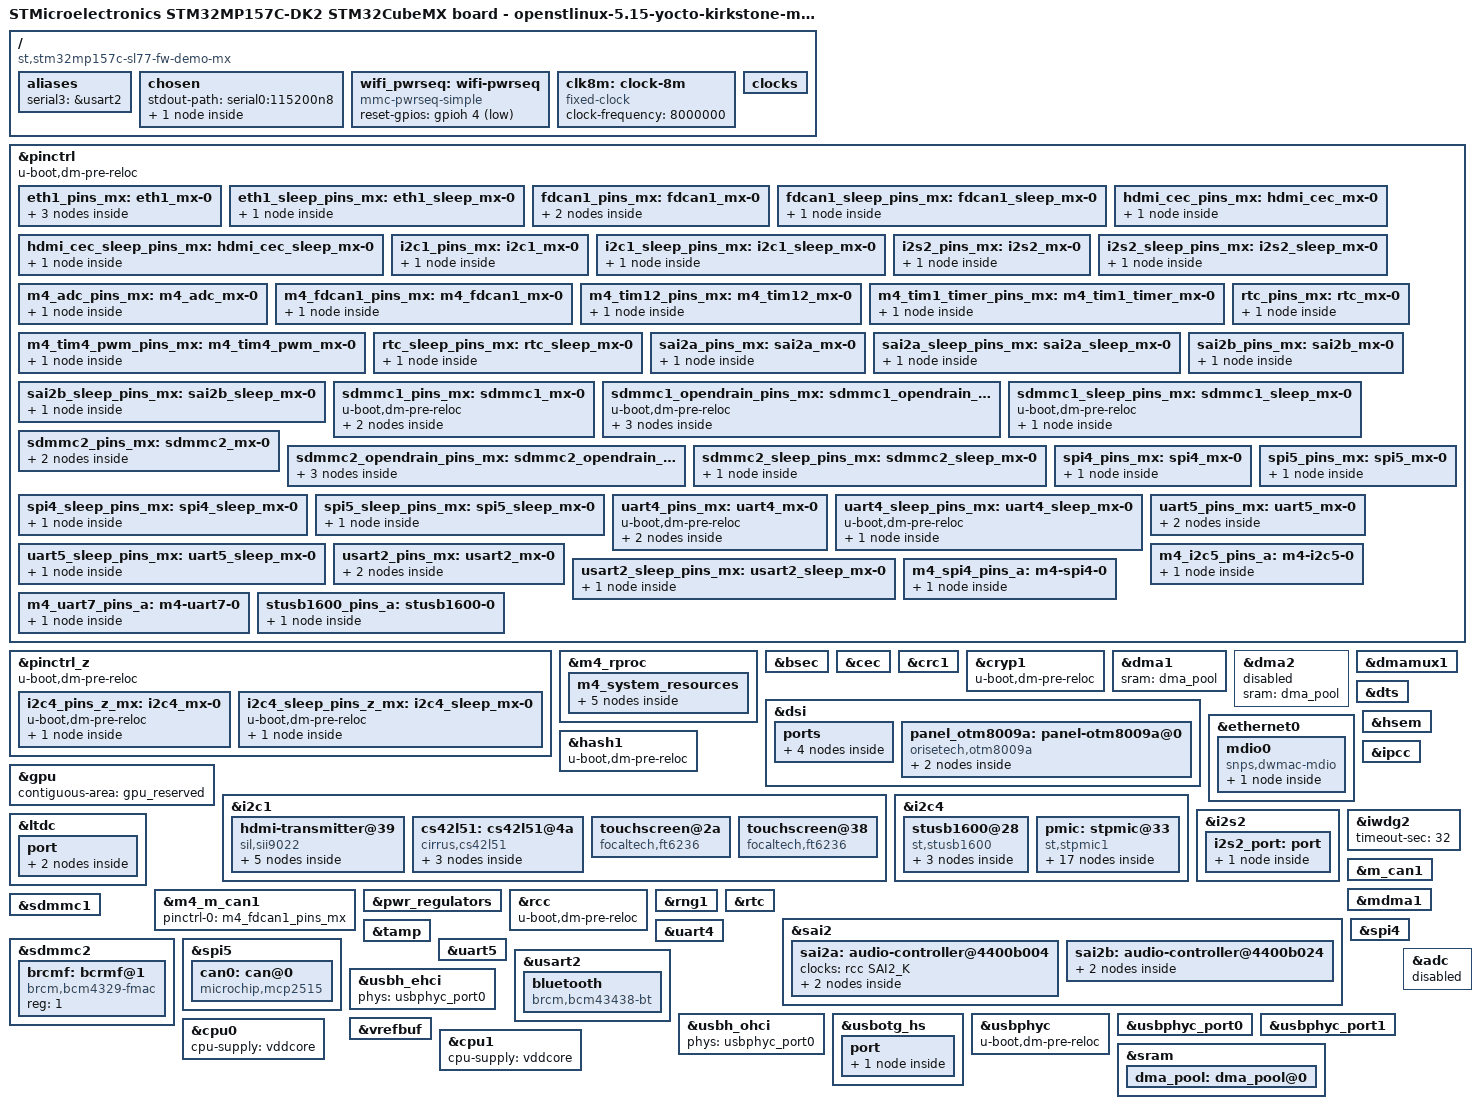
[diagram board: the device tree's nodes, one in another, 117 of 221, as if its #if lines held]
/*
 * Copyright (C) 2021 Slave77 - All Rights Reserved
 * Author: Slave77 <henry.slave77@gmail.com>
 */

/* 
 * For more information on Device Tree configuration, please refer to
 * https://wiki.st.com/stm32mpu/wiki/Category:Device_tree_configuration
 */

/dts-v1/;
#include <dt-bindings/pinctrl/stm32-pinfunc.h>

#include "stm32mp157.dtsi"
#include "stm32mp15xc.dtsi"
#include "stm32mp15-pinctrl.dtsi"
#include "stm32mp15xxac-pinctrl.dtsi"
#include "stm32mp15xx-dkx.dtsi"

/* USER CODE BEGIN includes */
#include <dt-bindings/mfd/st,stpmic1.h>
#include <dt-bindings/rtc/rtc-stm32.h>

/* USER CODE END includes */

/* USER CODE BEGIN defines */
#define USE_MCP2515

/* USER CODE END defines */


/ {
	model = "STMicroelectronics STM32MP157C-DK2 STM32CubeMX board - openstlinux-5.15-yocto-kirkstone-mp1-v22.06.15";
	compatible = "st,stm32mp157c-sl77-fw-demo-mx", "st,stm32mp157";

	aliases {
		serial3 = &usart2;
	};

	chosen {
		#address-cells = <1>;
		#size-cells = <1>;
		ranges;
		stdout-path = "serial0:115200n8";

		framebuffer {
			compatible = "simple-framebuffer";
			clocks = <&rcc LTDC_PX>;
			status = "disabled";
		};
	};

	wifi_pwrseq: wifi-pwrseq {
		compatible = "mmc-pwrseq-simple";
		reset-gpios = <&gpioh 4 GPIO_ACTIVE_LOW>;
	};

	/* Fixed crystal dedicated to mcp251x */
	clk8m: clock-8m {
		compatible = "fixed-clock";
		#clock-cells = <0>;
		clock-frequency = <8000000>;
	};
	/* USER CODE END root */

	clocks {
		/* USER CODE BEGIN clocks */
		/* USER CODE END clocks */

	};

}; /*root*/

&pinctrl {
	u-boot,dm-pre-reloc;

	eth1_pins_mx: eth1_mx-0 {
		pins1 {
			pinmux = <STM32_PINMUX('A', 1, AF11)>, /* ETH1_RX_CLK */
					 <STM32_PINMUX('A', 7, AF11)>, /* ETH1_RX_CTL */
					 <STM32_PINMUX('B', 0, AF11)>, /* ETH1_RXD2 */
					 <STM32_PINMUX('B', 1, AF11)>, /* ETH1_RXD3 */
					 <STM32_PINMUX('C', 4, AF11)>, /* ETH1_RXD0 */
					 <STM32_PINMUX('C', 5, AF11)>; /* ETH1_RXD1 */
			bias-disable;
		};
		pins2 {
			pinmux = <STM32_PINMUX('A', 2, AF11)>; /* ETH1_MDIO */
			bias-disable;
			drive-push-pull;
			slew-rate = <0>;
		};
		pins3 {
			pinmux = <STM32_PINMUX('B', 11, AF11)>, /* ETH1_TX_CTL */
					 <STM32_PINMUX('C', 1, AF11)>, /* ETH1_MDC */
					 <STM32_PINMUX('C', 2, AF11)>, /* ETH1_TXD2 */
					 <STM32_PINMUX('E', 2, AF11)>, /* ETH1_TXD3 */
					 <STM32_PINMUX('G', 4, AF11)>, /* ETH1_GTX_CLK */
					 <STM32_PINMUX('G', 5, AF11)>, /* ETH1_CLK125 */
					 <STM32_PINMUX('G', 13, AF11)>, /* ETH1_TXD0 */
					 <STM32_PINMUX('G', 14, AF11)>; /* ETH1_TXD1 */
			bias-disable;
			drive-push-pull;
			slew-rate = <2>;
		};
	};

	eth1_sleep_pins_mx: eth1_sleep_mx-0 {
		pins {
			pinmux = <STM32_PINMUX('A', 1, ANALOG)>, /* ETH1_RX_CLK */
					 <STM32_PINMUX('A', 2, ANALOG)>, /* ETH1_MDIO */
					 <STM32_PINMUX('A', 7, ANALOG)>, /* ETH1_RX_CTL */
					 <STM32_PINMUX('B', 0, ANALOG)>, /* ETH1_RXD2 */
					 <STM32_PINMUX('B', 1, ANALOG)>, /* ETH1_RXD3 */
					 <STM32_PINMUX('B', 11, ANALOG)>, /* ETH1_TX_CTL */
					 <STM32_PINMUX('C', 1, ANALOG)>, /* ETH1_MDC */
					 <STM32_PINMUX('C', 2, ANALOG)>, /* ETH1_TXD2 */
					 <STM32_PINMUX('C', 4, ANALOG)>, /* ETH1_RXD0 */
					 <STM32_PINMUX('C', 5, ANALOG)>, /* ETH1_RXD1 */
					 <STM32_PINMUX('E', 2, ANALOG)>, /* ETH1_TXD3 */
					 <STM32_PINMUX('G', 4, ANALOG)>, /* ETH1_GTX_CLK */
					 <STM32_PINMUX('G', 5, ANALOG)>, /* ETH1_CLK125 */
					 <STM32_PINMUX('G', 13, ANALOG)>, /* ETH1_TXD0 */
					 <STM32_PINMUX('G', 14, ANALOG)>; /* ETH1_TXD1 */
		};
	};

#ifdef CONFIG_FDCAN1_ON
	fdcan1_pins_mx: fdcan1_mx-0 {
		pins1 {
			pinmux = <STM32_PINMUX('A', 11, AF9)>; /* FDCAN1_RX */
			bias-disable;
		};
		pins2 {
			pinmux = <STM32_PINMUX('A', 12, AF9)>; /* FDCAN1_TX */
			bias-disable;
			drive-push-pull;
			slew-rate = <1>;
		};
	};

	fdcan1_sleep_pins_mx: fdcan1_sleep_mx-0 {
		pins {
			pinmux = <STM32_PINMUX('A', 11, ANALOG)>, /* FDCAN1_RX */
					 <STM32_PINMUX('A', 12, ANALOG)>; /* FDCAN1_TX */
		};
	};
#endif

	hdmi_cec_pins_mx: hdmi_cec_mx-0 {
		pins {
			pinmux = <STM32_PINMUX('B', 6, AF5)>; /* CEC */
			bias-disable;
			drive-open-drain;
			slew-rate = <0>;
		};
	};

	hdmi_cec_sleep_pins_mx: hdmi_cec_sleep_mx-0 {
		pins {
			pinmux = <STM32_PINMUX('B', 6, ANALOG)>; /* CEC */
		};
	};

	i2c1_pins_mx: i2c1_mx-0 {
		pins {
			pinmux = <STM32_PINMUX('D', 12, AF5)>, /* I2C1_SCL */
					 <STM32_PINMUX('F', 15, AF5)>; /* I2C1_SDA */
			bias-disable;
			drive-open-drain;
			slew-rate = <0>;
		};
	};

	i2c1_sleep_pins_mx: i2c1_sleep_mx-0 {
		pins {
			pinmux = <STM32_PINMUX('D', 12, ANALOG)>, /* I2C1_SCL */
					 <STM32_PINMUX('F', 15, ANALOG)>; /* I2C1_SDA */
		};
	};

	i2s2_pins_mx: i2s2_mx-0 {
		pins {
			pinmux = <STM32_PINMUX('A', 9, AF5)>, /* I2S2_CK */
					 <STM32_PINMUX('B', 9, AF5)>, /* I2S2_WS */
					 <STM32_PINMUX('I', 3, AF5)>; /* I2S2_SDO */
			bias-disable;
			drive-push-pull;
			slew-rate = <1>;
		};
	};

	i2s2_sleep_pins_mx: i2s2_sleep_mx-0 {
		pins {
			pinmux = <STM32_PINMUX('A', 9, ANALOG)>, /* I2S2_CK */
					 <STM32_PINMUX('B', 9, ANALOG)>, /* I2S2_WS */
					 <STM32_PINMUX('I', 3, ANALOG)>; /* I2S2_SDO */
		};
	};

	m4_adc_pins_mx: m4_adc_mx-0 {
		pins {
			pinmux = <STM32_PINMUX('A', 4, ANALOG)>, /* ADC1_INP18 */
					 <STM32_PINMUX('A', 5, ANALOG)>, /* ADC1_INP19 */
					 <STM32_PINMUX('F', 12, ANALOG)>; /* ADC1_INP6 */
		};
	};

	m4_fdcan1_pins_mx: m4_fdcan1_mx-0 {
		pins {
			pinmux = <STM32_PINMUX('A', 11, RSVD)>, /* FDCAN1_RX */
					 <STM32_PINMUX('A', 12, RSVD)>; /* FDCAN1_TX */
		};
	};

	m4_tim12_pins_mx: m4_tim12_mx-0 {
		pins {
			pinmux = <STM32_PINMUX('H', 6, RSVD)>; /* TIM12_CH1 */
		};
	};

	m4_tim1_timer_pins_mx: m4_tim1_timer_mx-0 {
		pins {
			pinmux = <STM32_PINMUX('A', 8, RSVD)>, /* TIM1_CH1 */
					 <STM32_PINMUX('E', 11, RSVD)>; /* TIM1_CH2 */
		};
	};

	m4_tim4_pwm_pins_mx: m4_tim4_pwm_mx-0 {
		pins {
			pinmux = <STM32_PINMUX('D', 14, RSVD)>, /* TIM4_CH3 */
					 <STM32_PINMUX('D', 15, RSVD)>; /* TIM4_CH4 */
		};
	};

	rtc_pins_mx: rtc_mx-0 {
		pins {
			pinmux = <STM32_PINMUX('I', 8, ANALOG)>; /* RTC_LSCO */
		};
	};

	rtc_sleep_pins_mx: rtc_sleep_mx-0 {
		pins {
			pinmux = <STM32_PINMUX('I', 8, ANALOG)>; /* RTC_LSCO */
		};
	};

	sai2a_pins_mx: sai2a_mx-0 {
		pins {
			pinmux = <STM32_PINMUX('E', 0, AF10)>, /* SAI2_MCLK_A */
					 <STM32_PINMUX('I', 5, AF10)>, /* SAI2_SCK_A */
					 <STM32_PINMUX('I', 6, AF10)>, /* SAI2_SD_A */
					 <STM32_PINMUX('I', 7, AF10)>; /* SAI2_FS_A */
			bias-disable;
			drive-push-pull;
			slew-rate = <0>;
		};
	};

	sai2a_sleep_pins_mx: sai2a_sleep_mx-0 {
		pins {
			pinmux = <STM32_PINMUX('E', 0, ANALOG)>, /* SAI2_MCLK_A */
					 <STM32_PINMUX('I', 5, ANALOG)>, /* SAI2_SCK_A */
					 <STM32_PINMUX('I', 6, ANALOG)>, /* SAI2_SD_A */
					 <STM32_PINMUX('I', 7, ANALOG)>; /* SAI2_FS_A */
		};
	};

	sai2b_pins_mx: sai2b_mx-0 {
		pins {
			pinmux = <STM32_PINMUX('F', 11, AF10)>; /* SAI2_SD_B */
			bias-disable;
			drive-push-pull;
			slew-rate = <0>;
		};
	};

	sai2b_sleep_pins_mx: sai2b_sleep_mx-0 {
		pins {
			pinmux = <STM32_PINMUX('F', 11, ANALOG)>; /* SAI2_SD_B */
		};
	};

	sdmmc1_pins_mx: sdmmc1_mx-0 {
		u-boot,dm-pre-reloc;
		pins1 {
			u-boot,dm-pre-reloc;
			pinmux = <STM32_PINMUX('C', 8, AF12)>, /* SDMMC1_D0 */
					 <STM32_PINMUX('C', 9, AF12)>, /* SDMMC1_D1 */
					 <STM32_PINMUX('C', 10, AF12)>, /* SDMMC1_D2 */
					 <STM32_PINMUX('C', 11, AF12)>, /* SDMMC1_D3 */
					 <STM32_PINMUX('D', 2, AF12)>; /* SDMMC1_CMD */
			bias-disable;
			drive-push-pull;
			slew-rate = <1>;
		};
		pins2 {
			u-boot,dm-pre-reloc;
			pinmux = <STM32_PINMUX('C', 12, AF12)>; /* SDMMC1_CK */
			bias-disable;
			drive-push-pull;
			slew-rate = <3>;
		};
	};

	sdmmc1_opendrain_pins_mx: sdmmc1_opendrain_mx-0 {
		u-boot,dm-pre-reloc;
		pins1 {
			u-boot,dm-pre-reloc;
			pinmux = <STM32_PINMUX('C', 8, AF12)>, /* SDMMC1_D0 */
					 <STM32_PINMUX('C', 9, AF12)>, /* SDMMC1_D1 */
					 <STM32_PINMUX('C', 10, AF12)>, /* SDMMC1_D2 */
					 <STM32_PINMUX('C', 11, AF12)>; /* SDMMC1_D3 */
			bias-disable;
			drive-push-pull;
			slew-rate = <1>;
		};
		pins2 {
			u-boot,dm-pre-reloc;
			pinmux = <STM32_PINMUX('C', 12, AF12)>; /* SDMMC1_CK */
			bias-disable;
			drive-push-pull;
			slew-rate = <3>;
		};
		pins3 {
			u-boot,dm-pre-reloc;
			pinmux = <STM32_PINMUX('D', 2, AF12)>; /* SDMMC1_CMD */
			bias-disable;
			drive-open-drain;
			slew-rate = <1>;
		};
	};

	sdmmc1_sleep_pins_mx: sdmmc1_sleep_mx-0 {
		u-boot,dm-pre-reloc;
		pins {
			u-boot,dm-pre-reloc;
			pinmux = <STM32_PINMUX('C', 8, ANALOG)>, /* SDMMC1_D0 */
					 <STM32_PINMUX('C', 9, ANALOG)>, /* SDMMC1_D1 */
					 <STM32_PINMUX('C', 10, ANALOG)>, /* SDMMC1_D2 */
					 <STM32_PINMUX('C', 11, ANALOG)>, /* SDMMC1_D3 */
					 <STM32_PINMUX('C', 12, ANALOG)>, /* SDMMC1_CK */
					 <STM32_PINMUX('D', 2, ANALOG)>; /* SDMMC1_CMD */
		};
	};

	sdmmc2_pins_mx: sdmmc2_mx-0 {
		pins1 {
			pinmux = <STM32_PINMUX('B', 3, AF9)>, /* SDMMC2_D2 */
					 <STM32_PINMUX('B', 4, AF9)>, /* SDMMC2_D3 */
					 <STM32_PINMUX('B', 14, AF9)>, /* SDMMC2_D0 */
					 <STM32_PINMUX('B', 15, AF9)>, /* SDMMC2_D1 */
					 <STM32_PINMUX('G', 6, AF10)>; /* SDMMC2_CMD */
			bias-disable;
			drive-push-pull;
			slew-rate = <1>;
		};
		pins2 {
			pinmux = <STM32_PINMUX('E', 3, AF9)>; /* SDMMC2_CK */
			bias-disable;
			drive-push-pull;
			slew-rate = <3>;
		};
	};

	sdmmc2_opendrain_pins_mx: sdmmc2_opendrain_mx-0 {
		pins1 {
			pinmux = <STM32_PINMUX('B', 3, AF9)>, /* SDMMC2_D2 */
					 <STM32_PINMUX('B', 4, AF9)>, /* SDMMC2_D3 */
					 <STM32_PINMUX('B', 14, AF9)>, /* SDMMC2_D0 */
					 <STM32_PINMUX('B', 15, AF9)>; /* SDMMC2_D1 */
			bias-disable;
			drive-push-pull;
			slew-rate = <1>;
		};
		pins2 {
			pinmux = <STM32_PINMUX('E', 3, AF9)>; /* SDMMC2_CK */
			bias-disable;
			drive-push-pull;
			slew-rate = <3>;
		};
		pins3 {
			pinmux = <STM32_PINMUX('G', 6, AF10)>; /* SDMMC2_CMD */
			bias-disable;
			drive-open-drain;
			slew-rate = <1>;
		};
	};

	sdmmc2_sleep_pins_mx: sdmmc2_sleep_mx-0 {
		pins {
			pinmux = <STM32_PINMUX('B', 3, ANALOG)>, /* SDMMC2_D2 */
					 <STM32_PINMUX('B', 4, ANALOG)>, /* SDMMC2_D3 */
					 <STM32_PINMUX('B', 14, ANALOG)>, /* SDMMC2_D0 */
					 <STM32_PINMUX('B', 15, ANALOG)>, /* SDMMC2_D1 */
					 <STM32_PINMUX('E', 3, ANALOG)>, /* SDMMC2_CK */
					 <STM32_PINMUX('G', 6, ANALOG)>; /* SDMMC2_CMD */
		};
	};

	spi4_pins_mx: spi4_mx-0 {
		pins {
			pinmux = <STM32_PINMUX('E', 12, AF5)>, /* SPI4_SCK */
					 <STM32_PINMUX('E', 13, AF5)>, /* SPI4_MISO */
					 <STM32_PINMUX('E', 14, AF5)>; /* SPI4_MOSI */
			bias-disable;
			drive-push-pull;
			slew-rate = <1>;
		};
	};

	spi4_sleep_pins_mx: spi4_sleep_mx-0 {
		pins {
			pinmux = <STM32_PINMUX('E', 12, ANALOG)>, /* SPI4_SCK */
					 <STM32_PINMUX('E', 13, ANALOG)>, /* SPI4_MISO */
					 <STM32_PINMUX('E', 14, ANALOG)>; /* SPI4_MOSI */
		};
	};

	spi5_pins_mx: spi5_mx-0 {
		pins {
			pinmux = <STM32_PINMUX('F', 7, AF5)>, /* SPI5_SCK */
					 <STM32_PINMUX('F', 8, AF5)>, /* SPI5_MISO */
					 <STM32_PINMUX('F', 9, AF5)>; /* SPI5_MOSI */
			bias-disable;
			drive-push-pull;
			slew-rate = <1>;
		};
	};

	spi5_sleep_pins_mx: spi5_sleep_mx-0 {
		pins {
			pinmux = <STM32_PINMUX('F', 7, ANALOG)>, /* SPI5_SCK */
					 <STM32_PINMUX('F', 8, ANALOG)>, /* SPI5_MISO */
					 <STM32_PINMUX('F', 9, ANALOG)>; /* SPI5_MOSI */
		};
	};

	uart4_pins_mx: uart4_mx-0 {
		u-boot,dm-pre-reloc;
		pins1 {
			u-boot,dm-pre-reloc;
			pinmux = <STM32_PINMUX('B', 2, AF8)>; /* UART4_RX */
			bias-disable;
		};
		pins2 {
			u-boot,dm-pre-reloc;
			pinmux = <STM32_PINMUX('G', 11, AF6)>; /* UART4_TX */
			bias-disable;
			drive-push-pull;
			slew-rate = <0>;
		};
	};

	uart4_sleep_pins_mx: uart4_sleep_mx-0 {
		u-boot,dm-pre-reloc;
		pins {
			u-boot,dm-pre-reloc;
			pinmux = <STM32_PINMUX('B', 2, ANALOG)>, /* UART4_RX */
					 <STM32_PINMUX('G', 11, ANALOG)>; /* UART4_TX */
		};
	};

	uart5_pins_mx: uart5_mx-0 {
		pins1 {
			pinmux = <STM32_PINMUX('B', 12, AF14)>; /* UART5_RX */
			bias-disable;
		};
		pins2 {
			pinmux = <STM32_PINMUX('B', 13, AF14)>; /* UART5_TX */
			bias-disable;
			drive-push-pull;
			slew-rate = <0>;
		};
	};

	uart5_sleep_pins_mx: uart5_sleep_mx-0 {
		pins {
			pinmux = <STM32_PINMUX('B', 12, ANALOG)>, /* UART5_RX */
					 <STM32_PINMUX('B', 13, ANALOG)>; /* UART5_TX */
		};
	};

	usart2_pins_mx: usart2_mx-0 {
		pins1 {
			pinmux = <STM32_PINMUX('D', 3, AF7)>, /* USART2_CTS */
					 <STM32_PINMUX('D', 6, AF7)>; /* USART2_RX */
			bias-disable;
		};
		pins2 {
			pinmux = <STM32_PINMUX('D', 4, AF7)>, /* USART2_RTS */
					 <STM32_PINMUX('D', 5, AF7)>; /* USART2_TX */
			bias-disable;
			drive-push-pull;
			slew-rate = <0>;
		};
	};

	usart2_sleep_pins_mx: usart2_sleep_mx-0 {
		pins {
			pinmux = <STM32_PINMUX('D', 3, ANALOG)>, /* USART2_CTS */
					 <STM32_PINMUX('D', 4, ANALOG)>, /* USART2_RTS */
					 <STM32_PINMUX('D', 5, ANALOG)>, /* USART2_TX */
					 <STM32_PINMUX('D', 6, ANALOG)>; /* USART2_RX */
		};
	};

	/* USER CODE BEGIN pinctrl */
	/* USER CODE END pinctrl */
};

&pinctrl_z {
	u-boot,dm-pre-reloc;

	i2c4_pins_z_mx: i2c4_mx-0 {
		u-boot,dm-pre-reloc;
		pins {
			u-boot,dm-pre-reloc;
			pinmux = <STM32_PINMUX('Z', 4, AF6)>, /* I2C4_SCL */
					 <STM32_PINMUX('Z', 5, AF6)>; /* I2C4_SDA */
			bias-disable;
			drive-open-drain;
			slew-rate = <0>;
		};
	};

	i2c4_sleep_pins_z_mx: i2c4_sleep_mx-0 {
		u-boot,dm-pre-reloc;
		pins {
			u-boot,dm-pre-reloc;
			pinmux = <STM32_PINMUX('Z', 4, ANALOG)>, /* I2C4_SCL */
					 <STM32_PINMUX('Z', 5, ANALOG)>; /* I2C4_SDA */
		};
	};

	/* USER CODE BEGIN pinctrl_z */
	/* USER CODE END pinctrl_z */
};

&m4_rproc{
	/*Restriction: "memory-region" property is not managed - please to use User-Section if needed*/
	mboxes = <&ipcc 0>, <&ipcc 1>, <&ipcc 2>;
	mbox-names = "vq0", "vq1", "shutdown";
	status = "okay";

	/* USER CODE BEGIN m4_rproc */
	memory-region = <&retram>, <&mcuram>, <&mcuram2>, <&vdev0vring0>, <&vdev0vring1>, <&vdev0buffer>;
	interrupt-parent = <&exti>;
	interrupts = <68 1>;
	wakeup-source;
	/* USER CODE END m4_rproc */

	m4_system_resources{
		#address-cells = <1>;
		#size-cells = <0>;

		status = "okay";

		/* USER CODE BEGIN m4_system_resources */
		m4_adc: adc@48003000 {
			compatible = "rproc-srm-dev";
			reg = <0x48003000 0x400>;
			clocks = <&rcc ADC12>, <&rcc ADC12_K>;
			clock-names = "bus", "adc";
			status = "disabled";
		};
		m4_dma2: dma@48001000 {
			compatible = "rproc-srm-dev";
			reg = <0x48001000 0x400>;
			clocks = <&rcc DMA2>;
			status = "disabled";
		};
		/*
		m4_m_can1: can@4400e000 {
			compatible = "rproc-srm-dev";
			reg = <0x4400e000 0x400>, <0x44011000 0x2800>;
			clocks = <&scmi0_clk CK_SCMI0_HSE>, <&rcc FDCAN_K>;
			clock-names = "hclk", "cclk";
			status = "disabled";
		};
		*/
		m4_timers1: timer@44000000 {
			compatible = "rproc-srm-dev";
			reg = <0x44000000 0x400>;
			clocks = <&rcc TIM1_K>;
			clock-names = "int";
			status = "disabled";
		};
		m4_timers12: timer@40006000 {
			compatible = "rproc-srm-dev";
			reg = <0x40006000 0x400>;
			clocks = <&rcc TIM12_K>;
			clock-names = "int";
			status = "disabled";
		};
		m4_timers4: timer@40002000 {
			compatible = "rproc-srm-dev";
			reg = <0x40002000 0x400>;
			clocks = <&rcc TIM4_K>;
			clock-names = "int";
			status = "disabled";
		};
		/* USER CODE END m4_system_resources */
	};
};

&bsec{
	status = "okay";

	/* USER CODE BEGIN bsec */
	/* USER CODE END bsec */
};

&cec{
	pinctrl-names = "default", "sleep";
	pinctrl-0 = <&hdmi_cec_pins_mx>;
	pinctrl-1 = <&hdmi_cec_sleep_pins_mx>;
	status = "okay";

	/* USER CODE BEGIN cec */
	/* USER CODE END cec */
};

&crc1{
	status = "okay";

	/* USER CODE BEGIN crc1 */
	/* USER CODE END crc1 */
};

&cryp1 {
	u-boot,dm-pre-reloc;
	status = "okay";

	/* USER CODE BEGIN cryp1 */
	/* USER CODE END cryp1 */
};

&dma1{
	status = "okay";

	/* USER CODE BEGIN dma1 */
	sram = <&dma_pool>;
	/* USER CODE END dma1 */
};

&dma2{
	status = "disabled";

	/* USER CODE BEGIN dma2 */
	sram = <&dma_pool>;
	/* USER CODE END dma2 */
};

&dmamux1{

	dma-masters = <&dma1>;
	dma-channels = <8>;

	status = "okay";

	/* USER CODE BEGIN dmamux1 */
	/* USER CODE END dmamux1 */
};

&dsi {
	status = "okay";

	/* USER CODE BEGIN dsi */
	#address-cells = <1>;
	#size-cells = <0>;

	ports {
		#address-cells = <1>;
		#size-cells = <0>;

		port@0 {
			reg = <0>;
			dsi_in: endpoint {
				remote-endpoint = <&ltdc_ep1_out>;
			};
		};

		port@1 {
			reg = <1>;
			dsi_out: endpoint {
				remote-endpoint = <&panel_in>;
			};
		};
	};

	panel_otm8009a: panel-otm8009a@0 {
		compatible = "orisetech,otm8009a";
		reg = <0>;
		reset-gpios = <&gpioe 4 GPIO_ACTIVE_LOW>;
		power-supply = <&v3v3>;
		status = "okay";

		port {
			panel_in: endpoint {
				remote-endpoint = <&dsi_out>;
			};
		};
	};
	/* USER CODE END dsi */
};

&dts{
	status = "okay";

	/* USER CODE BEGIN dts */
	/* USER CODE END dts */
};

&ethernet0{
	pinctrl-names = "default", "sleep";
	pinctrl-0 = <&eth1_pins_mx>;
	pinctrl-1 = <&eth1_sleep_pins_mx>;
	status = "okay";

	/* USER CODE BEGIN ethernet0 */
	phy-mode = "rgmii-id";
	max-speed = <1000>;
	phy-handle = <&phy0>;
	/*nvmem-cells = <&ethernet_mac_address>;
	nvmem-cell-names = "mac-address";*/

	mdio0{
		#address-cells = <1>;
		#size-cells = <0>;
		compatible = "snps,dwmac-mdio";

		phy0:ethernet-phy@0{
			reg = <0>;
		};
	};
	/* USER CODE END ethernet0 */
};

&gpu{
	status = "okay";

	/* USER CODE BEGIN gpu */
	contiguous-area = <&gpu_reserved>;
	/* USER CODE END gpu */
};

&hash1{
	u-boot,dm-pre-reloc;
	status = "okay";

	/* USER CODE BEGIN hash1 */
	/* USER CODE END hash1 */
};

&hsem{
	status = "okay";

	/* USER CODE BEGIN hsem */
	/* USER CODE END hsem */
};

&i2c1{
	pinctrl-names = "default", "sleep";
	pinctrl-0 = <&i2c1_pins_mx>;
	pinctrl-1 = <&i2c1_sleep_pins_mx>;
	status = "okay";

	/* USER CODE BEGIN i2c1 */
	i2c-scl-rising-time-ns = <100>;
	i2c-scl-falling-time-ns = <7>;
	/delete-property/ dmas;
	/delete-property/ dma-names;

	hdmi-transmitter@39{
		compatible = "sil,sii9022";
		reg = <0x39>;
		iovcc-supply = <&v3v3_hdmi>;
		cvcc12-supply = <&v1v2_hdmi>;
		reset-gpios = <&gpioa 10 GPIO_ACTIVE_LOW>;
		interrupts = <1 IRQ_TYPE_EDGE_FALLING>;
		interrupt-parent = <&gpiog>;
		#sound-dai-cells = <0>;
		status = "okay";

		ports{
			#address-cells = <1>;
			#size-cells = <0>;

			port@0{
				reg = <0>;

				sii9022_in:endpoint{
					remote-endpoint = <&ltdc_ep0_out>;
				};
			};

			port@3{
				reg = <3>;

				sii9022_tx_endpoint:endpoint{
					remote-endpoint = <&i2s2_endpoint>;
				};
			};
		};
	};

	cs42l51:cs42l51@4a{
		compatible = "cirrus,cs42l51";
		reg = <0x4a>;
		#sound-dai-cells = <0>;
		VL-supply = <&v3v3>;
		VD-supply = <&v1v8_audio>;
		VA-supply = <&v1v8_audio>;
		VAHP-supply = <&v1v8_audio>;
		reset-gpios = <&gpiog 9 GPIO_ACTIVE_LOW>;
		clocks = <&sai2a>;
		clock-names = "MCLK";
		status = "okay";

		cs42l51_port:port{
			#address-cells = <1>;
			#size-cells = <0>;

			cs42l51_tx_endpoint:endpoint@0{
				reg = <0>;
				remote-endpoint = <&sai2a_endpoint>;
				frame-master;
				bitclock-master;
			};

			cs42l51_rx_endpoint:endpoint@1{
				reg = <1>;
				remote-endpoint = <&sai2b_endpoint>;
				frame-master;
				bitclock-master;
			};
		};
	};

	touchscreen@2a{
		compatible = "focaltech,ft6236";
		reg = <0x2a>;
		interrupts = <2 2>;
		interrupt-parent = <&gpiof>;
		interrupt-controller;
		touchscreen-size-x = <480>;
		touchscreen-size-y = <800>;
		panel = <&panel_otm8009a>;
		status = "okay";
	};

	touchscreen@38 {
		compatible = "focaltech,ft6236";
		reg = <0x38>;
		interrupts = <2 2>;
		interrupt-parent = <&gpiof>;
		interrupt-controller;
		touchscreen-size-x = <480>;
		touchscreen-size-y = <800>;
		panel = <&panel_otm8009a>;
		vcc-supply = <&v3v3>;
		iovcc-supply = <&v3v3>;
		status = "okay";
	};
	/* USER CODE END i2c1 */
};

&i2c4{
	u-boot,dm-pre-reloc;
	pinctrl-names = "default", "sleep";
	pinctrl-0 = <&i2c4_pins_z_mx>;
	pinctrl-1 = <&i2c4_sleep_pins_z_mx>;
	status = "okay";

	/* USER CODE BEGIN i2c4 */
	i2c-scl-rising-time-ns = <185>;
	i2c-scl-falling-time-ns = <20>;
	clock-frequency = <400000>;
	/delete-property/ dmas;
	/delete-property/ dma-names;

	stusb1600@28{
		compatible = "st,stusb1600";
		reg = <0x28>;
		interrupts = <11 IRQ_TYPE_EDGE_FALLING>;
		interrupt-parent = <&gpioi>;
		pinctrl-names = "default";
		pinctrl-0 = <&stusb1600_pins_a>;
		status = "okay";
		vdd-supply = <&vin>;

		connector{
			compatible = "usb-c-connector";
			label = "USB-C";
			power-role = "dual";
			power-opmode = "default";

			port{

				con_usbotg_hs_ep:endpoint{
					remote-endpoint = <&usbotg_hs_ep>;
				};
			};
		};
	};

	pmic:stpmic@33{
		compatible = "st,stpmic1";
		reg = <0x33>;
		interrupts-extended = <&exti_pwr 55 IRQ_TYPE_EDGE_FALLING>;
		interrupt-controller;
		#interrupt-cells = <2>;
		status = "okay";

		regulators{
			compatible = "st,stpmic1-regulators";
			buck1-supply = <&vin>;
			buck2-supply = <&vin>;
			buck3-supply = <&vin>;
			buck4-supply = <&vin>;
			ldo1-supply = <&v3v3>;
			ldo2-supply = <&vin>;
			ldo3-supply = <&vdd_ddr>;
			ldo4-supply = <&vin>;
			ldo5-supply = <&vin>;
			ldo6-supply = <&v3v3>;
			vref_ddr-supply = <&vin>;
			boost-supply = <&vin>;
			pwr_sw1-supply = <&bst_out>;
			pwr_sw2-supply = <&bst_out>;

			vddcore:buck1{
				regulator-name = "vddcore";
				regulator-min-microvolt = <1200000>;
				regulator-max-microvolt = <1350000>;
				regulator-always-on;
				regulator-initial-mode = <0>;
				regulator-over-current-protection;
			};

			vdd_ddr:buck2{
				regulator-name = "vdd_ddr";
				regulator-min-microvolt = <1350000>;
				regulator-max-microvolt = <1350000>;
				regulator-always-on;
				regulator-initial-mode = <0>;
				regulator-over-current-protection;
			};

			vdd:buck3{
				regulator-name = "vdd";
				regulator-min-microvolt = <3300000>;
				regulator-max-microvolt = <3300000>;
				regulator-always-on;
				st,mask-reset;
				regulator-initial-mode = <0>;
				regulator-over-current-protection;
			};

			v3v3:buck4{
				regulator-name = "v3v3";
				regulator-min-microvolt = <3300000>;
				regulator-max-microvolt = <3300000>;
				regulator-always-on;
				regulator-over-current-protection;
				regulator-initial-mode = <0>;
			};

/*
			v5v0:buck5{
				regulator-name = "v5v0";
				regulator-min-microvolt = <5000000>;
				regulator-max-microvolt = <5000000>;
				regulator-always-on;
				regulator-over-current-protection;
				regulator-initial-mode = <0>;
			};
*/

			v1v8_audio:ldo1{
				regulator-name = "v1v8_audio";
				regulator-min-microvolt = <1800000>;
				regulator-max-microvolt = <1800000>;
				regulator-always-on;
				interrupts = <IT_CURLIM_LDO1 0>;
			};

			v3v3_hdmi:ldo2{
				regulator-name = "v3v3_hdmi";
				regulator-min-microvolt = <3300000>;
				regulator-max-microvolt = <3300000>;
				regulator-always-on;
				interrupts = <IT_CURLIM_LDO2 0>;
			};

			vtt_ddr:ldo3{
				regulator-name = "vtt_ddr";
				regulator-min-microvolt = <500000>;
				regulator-max-microvolt = <750000>;
				regulator-always-on;
				regulator-over-current-protection;
			};

			vdd_usb:ldo4{
				regulator-name = "vdd_usb";
				regulator-min-microvolt = <3300000>;
				regulator-max-microvolt = <3300000>;
				interrupts = <IT_CURLIM_LDO4 0>;
				regulator-always-on;
			};

			vdda:ldo5{
				regulator-name = "vdda";
				regulator-min-microvolt = <2900000>;
				regulator-max-microvolt = <2900000>;
				interrupts = <IT_CURLIM_LDO5 0>;
				regulator-boot-on;
			};

			v1v2_hdmi:ldo6{
				regulator-name = "v1v2_hdmi";
				regulator-min-microvolt = <1200000>;
				regulator-max-microvolt = <1200000>;
				regulator-always-on;
				interrupts = <IT_CURLIM_LDO6 0>;
			};

			vref_ddr:vref_ddr{
				regulator-name = "vref_ddr";
				regulator-always-on;
				regulator-over-current-protection;
			};

			bst_out:boost{
				regulator-name = "bst_out";
				interrupts = <IT_OCP_BOOST 0>;
			};

			vbus_otg:pwr_sw1{
				regulator-name = "vbus_otg";
				interrupts = <IT_OCP_OTG 0>;
			};

			vbus_sw:pwr_sw2{
				regulator-name = "vbus_sw";
				interrupts = <IT_OCP_SWOUT 0>;
				regulator-active-discharge = <1>;
			};
		};

		onkey{
			compatible = "st,stpmic1-onkey";
			interrupts = <IT_PONKEY_F 0>, <IT_PONKEY_R 0>;
			interrupt-names = "onkey-falling", "onkey-rising";
			power-off-time-sec = <10>;
			status = "okay";
		};

		watchdog{
			compatible = "st,stpmic1-wdt";
			status = "disabled";
		};
	};
	/* USER CODE END i2c4 */
};

&i2s2{
	pinctrl-names = "default", "sleep";
	pinctrl-0 = <&i2s2_pins_mx>;
	pinctrl-1 = <&i2s2_sleep_pins_mx>;
	status = "okay";

	/* USER CODE BEGIN i2s2 */
	clocks = <&rcc SPI2>, <&rcc SPI2_K>, <&rcc PLL3_Q>, <&rcc PLL3_R>;
	clock-names = "pclk", "i2sclk", "x8k", "x11k";

	i2s2_port:port{

		i2s2_endpoint:endpoint{
			remote-endpoint = <&sii9022_tx_endpoint>;
			format = "i2s";
			mclk-fs = <256>;
		};
	};
	/* USER CODE END i2s2 */
};

&ipcc{
	status = "okay";

	/* USER CODE BEGIN ipcc */
	/* USER CODE END ipcc */
};

&iwdg2{
	status = "okay";

	/* USER CODE BEGIN iwdg2 */
	timeout-sec = <32>;
	/* USER CODE END iwdg2 */
};

&ltdc {
	status = "okay";

	/* USER CODE BEGIN ltdc */

	port {
		#address-cells = <1>;
		#size-cells = <0>;

		ltdc_ep0_out:endpoint@0{
			reg = <0>;
			remote-endpoint = <&sii9022_in>;
		};

		ltdc_ep1_out: endpoint@1 {
			reg = <1>;
			remote-endpoint = <&dsi_in>;
		};
	};
	/* USER CODE END ltdc */
};

#ifdef CONFIG_FDCAN1_ON
&m_can1{
	pinctrl-names = "default", "sleep";
	pinctrl-0 = <&fdcan1_pins_mx>;
	pinctrl-1 = <&fdcan1_sleep_pins_mx> /* RESTORE!!! ; */
	status = "okay";

	/* USER CODE BEGIN m_can1 */
	/* USER CODE END m_can1 */
};
#endif

&m4_adc{
	pinctrl-names = "default";
	pinctrl-0 = <&m4_adc_pins_mx>;
	status = "okay";

	/* USER CODE BEGIN m4_adc */
	/* USER CODE END m4_adc */
};

&m4_dma2{
	status = "okay";

	/* USER CODE BEGIN m4_dma2 */
	/* USER CODE END m4_dma2 */
};

&m4_m_can1{
	pinctrl-names = "default";
	pinctrl-0 = <&m4_fdcan1_pins_mx>;
	status = "okay";

	/* USER CODE BEGIN m4_m_can1 */
	/* USER CODE END m4_m_can1 */
};

&m4_timers1{
	pinctrl-names = "default";
	pinctrl-0 = <&m4_tim1_timer_pins_mx>;
	status = "okay";

	/* USER CODE BEGIN m4_timers1 */
	/* USER CODE END m4_timers1 */
};

&m4_timers12{
	pinctrl-names = "default";
	pinctrl-0 = <&m4_tim12_pins_mx>;
	status = "okay";

	/* USER CODE BEGIN m4_timers12 */
	/* USER CODE END m4_timers12 */
};

&m4_timers4{
	pinctrl-names = "default";
	pinctrl-0 = <&m4_tim4_pwm_pins_mx>;
	status = "okay";

	/* USER CODE BEGIN m4_timers4 */
	/* USER CODE END m4_timers4 */
};

&mdma1{
	status = "okay";

	/* USER CODE BEGIN mdma1 */
	/* USER CODE END mdma1 */
};

&pwr_regulators{
	status = "okay";

	/* USER CODE BEGIN pwr_regulators */
	vdd-supply = <&vdd>;
	vdd_3v3_usbfs-supply = <&vdd_usb>;
	/* USER CODE END pwr_regulators */
};

&rcc{
	u-boot,dm-pre-reloc;
	status = "okay";

	/* USER CODE BEGIN rcc */
	/* USER CODE END rcc */
};

&rng1{
	status = "okay";

	/* USER CODE BEGIN rng1 */
	/* USER CODE END rng1 */
};

&rtc{
	pinctrl-names = "default", "sleep";
	pinctrl-0 = <&rtc_pins_mx>;
	pinctrl-1 = <&rtc_sleep_pins_mx>;
	status = "okay";

	/* USER CODE BEGIN rtc */
	st,lsco = <RTC_OUT2_RMP>;
	pinctrl-0 = <&rtc_out2_rmp_pins_a>;
	pinctrl-names = "default";
	/* USER CODE END rtc */
};

&sai2{
	pinctrl-names = "default", "sleep";
	pinctrl-0 = <&sai2a_pins_mx>, <&sai2b_pins_mx>;
	pinctrl-1 = <&sai2a_sleep_pins_mx>, <&sai2b_sleep_pins_mx>;
	status = "okay";

	/* USER CODE BEGIN sai2 */
	clocks = <&rcc SAI2>, <&rcc PLL3_Q>, <&rcc PLL3_R>;
	clock-names = "pclk", "x8k", "x11k";
	/* USER CODE END sai2 */

	sai2a:audio-controller@4400b004{
		status = "okay";

		/* USER CODE BEGIN sai2a */
		#clock-cells = <0>;
		dma-names = "tx";
		clocks = <&rcc SAI2_K>;
		clock-names = "sai_ck";

		sai2a_port:port{

			sai2a_endpoint:endpoint{
				remote-endpoint = <&cs42l51_tx_endpoint>;
				format = "i2s";
				mclk-fs = <256>;
				dai-tdm-slot-num = <2>;
				dai-tdm-slot-width = <32>;
			};
		};
		/* USER CODE END sai2a */
	};

	sai2b:audio-controller@4400b024{
		status = "okay";

		/* USER CODE BEGIN sai2b */
		dma-names = "rx";
		st,sync = <&sai2a 2>;
		clocks = <&rcc SAI2_K>, <&sai2a>;
		clock-names = "sai_ck", "MCLK";

		sai2b_port:port{

			sai2b_endpoint:endpoint{
				remote-endpoint = <&cs42l51_rx_endpoint>;
				format = "i2s";
				mclk-fs = <256>;
				dai-tdm-slot-num = <2>;
				dai-tdm-slot-width = <32>;
			};
		};
		/* USER CODE END sai2b */
	};
};

&sdmmc1{
	u-boot,dm-pre-reloc;
	pinctrl-names = "default", "opendrain", "sleep";
	pinctrl-0 = <&sdmmc1_pins_mx>;
	pinctrl-1 = <&sdmmc1_opendrain_pins_mx>;
	pinctrl-2 = <&sdmmc1_sleep_pins_mx>;
	status = "okay";

	/* USER CODE BEGIN sdmmc1 */
	cd-gpios = <&gpiob 7 (GPIO_ACTIVE_LOW | GPIO_PULL_UP)>;
	disable-wp;
	st,neg-edge;
	bus-width = <4>;
	vmmc-supply = <&v3v3>;
	/* USER CODE END sdmmc1 */
};

/* Wifi */
&sdmmc2{
	arm,primecell-periphid = <0x10153180>;
	pinctrl-names = "default", "opendrain", "sleep";
	pinctrl-0 = <&sdmmc2_b4_pins_a>;
	pinctrl-1 = <&sdmmc2_b4_od_pins_a>;
	pinctrl-2 = <&sdmmc2_b4_sleep_pins_a>;

	/* USER CODE BEGIN sdmmc2 */
	non-removable;
	st,neg-edge;
	bus-width = <4>;
	vmmc-supply = <&v3v3>;
	mmc-pwrseq = <&wifi_pwrseq>;
	#address-cells = <1>;
	#size-cells = <0>;
	status = "okay";

	brcmf: bcrmf@1 {
		reg = <1>;
		compatible = "brcm,bcm4329-fmac";
	};
	/* USER CODE END sdmmc2 */
};

&spi4{
	pinctrl-names = "default", "sleep";
	pinctrl-0 = <&spi4_pins_mx>;
	pinctrl-1 = <&spi4_sleep_pins_mx>;
	status = "okay";

	/* USER CODE BEGIN spi4 */
	/* USER CODE END spi4 */
};

&spi5{
	pinctrl-names = "default", "sleep";
	pinctrl-0 = <&spi5_pins_mx>;
	pinctrl-1 = <&spi5_sleep_pins_mx>;
	cs-gpios = <&gpiof 6 0>;
//	spi-max-frequency = <10000000>;
	status = "okay";

	/* USER CODE BEGIN spi5 */
#ifdef USE_MCP2515
	can0: can@0 {
		compatible = "microchip,mcp2515";
		reg = <0>;
		clocks = <&clk8m>;
		interrupts = <4 IRQ_TYPE_EDGE_FALLING>;
		interrupt-parent = <&gpiof>;
		spi-max-frequency = <10000000>;
	};
#else
	spidev@0{
		compatible = "rohm,dh2228fv";	/* Same as "spidev" but without errors at boot. Search "buggy DT" to understand */
		reg = <0>;
		spi-max-frequency = <10000000>;
	};
#endif
	/* USER CODE END spi5 */
};

&tamp{
	status = "okay";

	/* USER CODE BEGIN tamp */
	/* USER CODE END tamp */
};

&uart4{
	u-boot,dm-pre-reloc;
	pinctrl-names = "default", "sleep";
	pinctrl-0 = <&uart4_pins_mx>;
	pinctrl-1 = <&uart4_sleep_pins_mx>;
	status = "okay";

	/* USER CODE BEGIN uart4 */
	/delete-property/ dmas;
	/delete-property/ dma-names;
	/* USER CODE END uart4 */
};

&uart5{
	pinctrl-names = "default", "sleep";
	pinctrl-0 = <&uart5_pins_mx>;
	pinctrl-1 = <&uart5_sleep_pins_mx>;
	status = "okay";

	/* USER CODE BEGIN uart5 */
	/* USER CODE END uart5 */
};

/* Bluetooth */
&usart2 {
	pinctrl-names = "default", "sleep", "idle";
	pinctrl-0 = <&usart2_pins_c>;
	pinctrl-1 = <&usart2_sleep_pins_c>;
	pinctrl-2 = <&usart2_idle_pins_c>;

	/* USER CODE BEGIN usart2 */
	uart-has-rtscts;
	status = "okay";

	bluetooth {
		shutdown-gpios = <&gpioz 6 GPIO_ACTIVE_HIGH>;
		compatible = "brcm,bcm43438-bt";
		max-speed = <3000000>;
		vbat-supply = <&v3v3>;
		vddio-supply = <&v3v3>;
	};
	/* USER CODE END usart2 */
};

&usbh_ehci{
	status = "okay";

	/* USER CODE BEGIN usbh_ehci */
	phys = <&usbphyc_port0>;
	/* USER CODE END usbh_ehci */
};

&usbh_ohci{
	status = "okay";

	/* USER CODE BEGIN usbh_ohci */
	/* USER CODE END usbh_ohci */
};

&usbotg_hs{
	u-boot,dm-pre-reloc;
	status = "okay";

	/* USER CODE BEGIN usbotg_hs */
	phys = <&usbphyc_port1 0>;
	phy-names = "usb2-phy";
	usb-role-switch;

	port{

		usbotg_hs_ep:endpoint{
			remote-endpoint = <&con_usbotg_hs_ep>;
		};
	};
	/* USER CODE END usbotg_hs */
};

&usbphyc{
	u-boot,dm-pre-reloc;
	status = "okay";

	/* USER CODE BEGIN usbphyc */
	/* USER CODE END usbphyc */
};

#ifdef PIPPO
&usbphyc_port0{
	u-boot,dm-pre-reloc;
	status = "okay";

	/* USER CODE BEGIN usbphyc_port0 */
	phy-supply = <&vdd_usb>;
	st,phy-tuning = <&usb_phy_tuning>;
	/* USER CODE END usbphyc_port0 */
};

&usbphyc_port1{
	u-boot,dm-pre-reloc;
	status = "okay";

	/* USER CODE BEGIN usbphyc_port1 */
	phy-supply = <&vdd_usb>;
	st,phy-tuning = <&usb_phy_tuning>;
	/* USER CODE END usbphyc_port1 */
};
#endif

&vrefbuf{
	status = "okay";

	/* USER CODE BEGIN vrefbuf */
	regulator-min-microvolt = <2500000>;
	regulator-max-microvolt = <2500000>;
	vdda-supply = <&vdd>;
	/* USER CODE END vrefbuf */
};

/* USER CODE BEGIN addons */
&adc {
	status = "disabled";
};

&pinctrl{

	m4_i2c5_pins_a: m4-i2c5-0 {
		pins {
			pinmux = <STM32_PINMUX('A', 11, RSVD)>, /* I2C5_SCL */
				 <STM32_PINMUX('A', 12, RSVD)>; /* I2C5_SDA */
		};
	};

	m4_spi4_pins_a: m4-spi4-0 {
		pins {
			pinmux = <STM32_PINMUX('E', 12, RSVD)>, /* SPI4_SCK */
				 <STM32_PINMUX('E', 14, RSVD)>, /* SPI4_MOSI */
				 <STM32_PINMUX('E', 13, RSVD)>; /* SPI4_MISO */
		};
	};

	m4_uart7_pins_a: m4-uart7-0 {
		pins {
			pinmux = <STM32_PINMUX('E', 8, RSVD)>, /* USART7_TX */
				 <STM32_PINMUX('E', 7, RSVD)>; /* USART7_RX */
		};
	};

	stusb1600_pins_a:stusb1600-0{

		pins{
			bias-pull-up;
			pinmux = <STM32_PINMUX('I', 11, ANALOG)>;
		};
	};
};

&usbh_ohci{
	phys = <&usbphyc_port0>;
};

&cpu0{
	cpu-supply = <&vddcore>;
};

&cpu1{
	cpu-supply = <&vddcore>;
};

&sram{

	dma_pool:dma_pool@0{
		reg = <0x50000 0x10000>;
		pool;
	};
};
/* USER CODE END addons */

